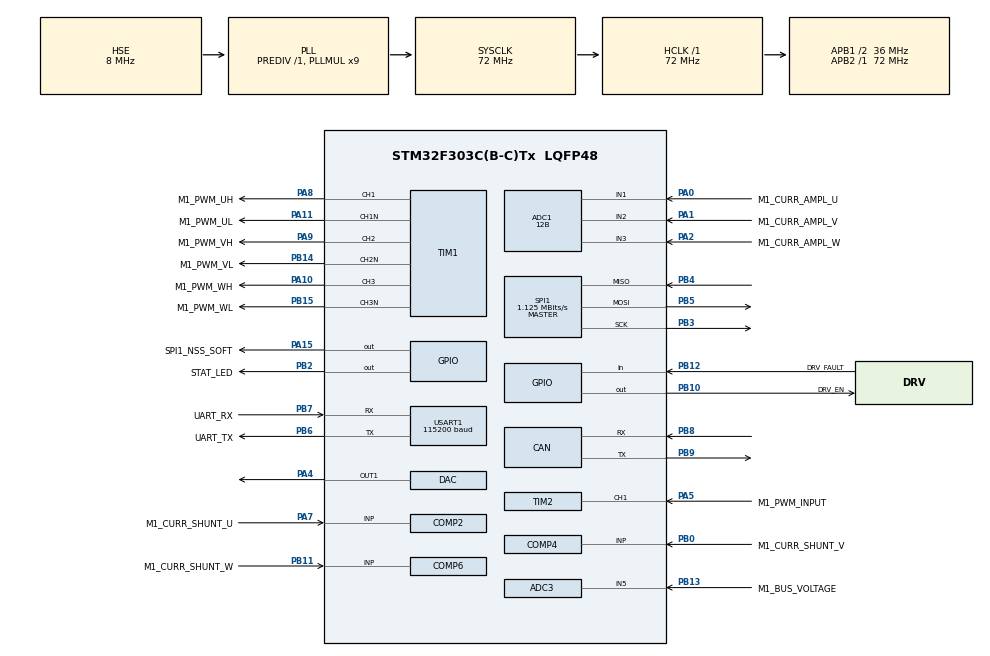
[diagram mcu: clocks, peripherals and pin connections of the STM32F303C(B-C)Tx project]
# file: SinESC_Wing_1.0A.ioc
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ADC1.Channel-1\#ChannelRegularConversion=ADC_CHANNEL_1
ADC1.ClockPrescaler=ADC_CLOCK_SYNC_PCLK_DIV1
ADC1.ContinuousConvMode=DISABLE
ADC1.DMAContinuousRequests=DISABLE
ADC1.DataAlign=ADC_DATAALIGN_LEFT
ADC1.DiscontinuousConvMode=DISABLE
ADC1.EOCSelection=ADC_EOC_SINGLE_CONV
ADC1.EnableAnalogWatchDog1=false
ADC1.EnableAnalogWatchDog2=false
ADC1.EnableAnalogWatchDog3=false
ADC1.EnableInjectedConversion=ENABLE
ADC1.EnableRegularConversion=ENABLE
ADC1.ExternalTrigConv=ADC_SOFTWARE_START
ADC1.ExternalTrigConvEdge=ADC_EXTERNALTRIGCONVEDGE_NONE
ADC1.ExternalTrigInjecConv=ADC_EXTERNALTRIGINJECCONV_T1_TRGO
ADC1.ExternalTrigInjecConvEdge=ADC_EXTERNALTRIGINJECCONV_EDGE_RISING
ADC1.InjNumberOfConversion=3
ADC1.InjectedChannel-1\#ChannelInjectedConversion=ADC_CHANNEL_1
ADC1.InjectedChannel-2\#ChannelInjectedConversion=ADC_CHANNEL_2
ADC1.InjectedChannel-3\#ChannelInjectedConversion=ADC_CHANNEL_3
ADC1.InjectedConvMode=None
ADC1.InjectedOffset-1\#ChannelInjectedConversion=0
ADC1.InjectedOffset-2\#ChannelInjectedConversion=0
ADC1.InjectedOffset-3\#ChannelInjectedConversion=0
ADC1.InjectedOffsetNumber-1\#ChannelInjectedConversion=ADC_OFFSET_NONE
ADC1.InjectedOffsetNumber-2\#ChannelInjectedConversion=ADC_OFFSET_NONE
ADC1.InjectedOffsetNumber-3\#ChannelInjectedConversion=ADC_OFFSET_NONE
ADC1.InjectedRank-1\#ChannelInjectedConversion=1
ADC1.InjectedRank-2\#ChannelInjectedConversion=2
ADC1.InjectedRank-3\#ChannelInjectedConversion=3
ADC1.InjectedSamplingTime-1\#ChannelInjectedConversion=ADC_SAMPLETIME_7CYCLES_5
ADC1.InjectedSamplingTime-2\#ChannelInjectedConversion=ADC_SAMPLETIME_7CYCLES_5
ADC1.InjectedSamplingTime-3\#ChannelInjectedConversion=ADC_SAMPLETIME_7CYCLES_5
ADC1.LowPowerAutoWait=DISABLE
ADC1.NbrOfConversion=1
ADC1.NbrOfConversionFlag=1
ADC1.Offset-1\#ChannelRegularConversion=0
ADC1.OffsetNumber-1\#ChannelRegularConversion=ADC_OFFSET_NONE
ADC1.Overrun=ADC_OVR_DATA_PRESERVED
ADC1.QueueInjectedContext=ENABLE
ADC1.Rank-1\#ChannelRegularConversion=1
ADC1.Resolution=ADC_RESOLUTION_12B
ADC1.SamplingTime-1\#ChannelRegularConversion=ADC_SAMPLETIME_19CYCLES_5
ADC1.ScanConvMode=ADC_SCAN_ENABLE
ADC1.master=1
ADC3.Channel-1\#ChannelRegularConversion=ADC_CHANNEL_5
ADC3.ClockPrescaler=ADC_CLOCK_SYNC_PCLK_DIV1
ADC3.ContinuousConvMode=DISABLE
ADC3.DMAContinuousRequests=DISABLE
ADC3.DataAlign=ADC_DATAALIGN_LEFT
ADC3.DiscontinuousConvMode=DISABLE
ADC3.EOCSelection=ADC_EOC_SINGLE_CONV
ADC3.EnableAnalogWatchDog1=false
ADC3.EnableAnalogWatchDog2=false
ADC3.EnableAnalogWatchDog3=false
ADC3.EnableRegularConversion=ENABLE
ADC3.ExternalTrigConv=ADC_SOFTWARE_START
ADC3.ExternalTrigConvEdge=ADC_EXTERNALTRIGCONVEDGE_NONE
ADC3.LowPowerAutoWait=DISABLE
ADC3.NbrOfConversion=1
ADC3.NbrOfConversionFlag=1
ADC3.Offset-1\#ChannelRegularConversion=0
ADC3.OffsetNumber-1\#ChannelRegularConversion=ADC_OFFSET_NONE
ADC3.Overrun=ADC_OVR_DATA_PRESERVED
ADC3.Rank-1\#ChannelRegularConversion=1
ADC3.Resolution=ADC_RESOLUTION_12B
ADC3.SamplingTime-1\#ChannelRegularConversion=ADC_SAMPLETIME_19CYCLES_5
ADC3.ScanConvMode=ADC_SCAN_DISABLE
ADC3.master=1
CAN.CalculateTimeQuantum=444.44444444444446
COMP2.InvertingInput=COMP_INVERTINGINPUT_1_2VREFINT
COMP2.Output=COMP_OUTPUT_TIM1BKIN2
COMP4.InvertingInput=COMP_INVERTINGINPUT_1_2VREFINT
COMP4.Output=COMP_OUTPUT_TIM1BKIN2
COMP6.InvertingInput=COMP_INVERTINGINPUT_1_2VREFINT
COMP6.Output=COMP_OUTPUT_TIM1BKIN2
ExtraMW=MotorControl
ExtraMW.MotorControl.Config=MotorControl
ExtraMW.MotorControl.Mode=MotorControl
ExtraMW.MotorControl.Root=MCSDK_v5.4.4/MotorControl
ExtraMW.MotorControl.Template=templates
Mcu.Family=STM32F3
Mcu.Name=STM32F303C(B-C)Tx
Mcu.Package=LQFP48
MotorControl.ADC_1_PERIPH=ADC1
MotorControl.ADC_2_PERIPH=ADC2
MotorControl.ADC_AHBPERIPH=RCC_AHBPeriph_ADC12
MotorControl.ADC_CLOCK_WB_DIV=1
MotorControl.ADC_CLOCK_WB_FREQ=72
MotorControl.ADC_PERIPH=ADC1
MotorControl.ADC_REFERENCE_VOLTAGE=3.30
MotorControl.ALIGNMENT_ANGLE_DEG=90
MotorControl.ALIGNMENT_DURATION=700
MotorControl.AMPLIFICATION_GAIN=29.77
MotorControl.ANGC={0,0,0,0,0,0,0,0}
MotorControl.BEMF_CONSISTENCY_GAIN=64
MotorControl.BEMF_CONSISTENCY_TOL=64
MotorControl.BKIN1_FILTER=0
MotorControl.BKIN2_FILTER=3
MotorControl.BKIN2_MODE=INT_MODE
MotorControl.BKIN_MODE=NONE
MotorControl.BOARD=CUSTOM
MotorControl.BRKIN2_GPIO_AF=GPIO_AF_2
MotorControl.BRKIN_GPIO_AF=GPIO_AF_12
MotorControl.BUS_VOLTAGE_READING=true
MotorControl.CCMRAM_ENABLED=false
MotorControl.CLOCK_FREQUENCY=CPU_CLK_72_MHZ
MotorControl.CLOCK_SOURCE=EXTERNAL
MotorControl.CONSTANT1_D=222297
MotorControl.CONSTANT1_Q=222297
MotorControl.CONSTANT2_QD=37693
MotorControl.CORD_BEMF_CONSISTENCY_GAIN=64
MotorControl.CORD_BEMF_CONSISTENCY_TOL=64
MotorControl.CORD_F1=16384
MotorControl.CORD_F2=8192
MotorControl.CORD_FIFO_DEPTH_01HZ=64
MotorControl.CORD_FIFO_DEPTH_DPP=64
MotorControl.CORD_GAIN1=-18535
MotorControl.CORD_GAIN2=22294
MotorControl.CORD_MAX_ACCEL_DPPP=30
MotorControl.CORD_MEAS_ERRORS_BEFORE_FAULTS=3
MotorControl.CORD_VARIANCE_THRESHOLD=4
MotorControl.CPU_CLK_72_MHZ=true
MotorControl.CTRBDID=10013
MotorControl.CUBE_MX_VER=5.6.1
MotorControl.CURRENT_READING_TOPOLOGY=THREE_SHUNT
MotorControl.CURR_SAMPLING_TIME=1
MotorControl.DAC_EMULATED=false
MotorControl.DAC_FUNCTIONALITY=false
MotorControl.DAC_TIMER_CH1_GPIO_PIN=LL_GPIO_PIN_4
MotorControl.DAC_TIMER_CH1_GPIO_PORT=GPIOA
MotorControl.DAC_TIMER_CH2_GPIO_PIN=LL_GPIO_PIN_0
MotorControl.DAC_TIMER_CH2_GPIO_PORT=GPIOA
MotorControl.DAC_TIMER_SELECTION=TIM3
MotorControl.DC_CURRENT_RS_MEAS=21.00
MotorControl.DEBUG_DAC_CH1=false
MotorControl.DEBUG_DAC_CH2=false
MotorControl.DEFAULT_CONTROL_MODE=STC_SPEED_MODE
MotorControl.DEFAULT_DAC_CHANNEL_1=MC_PROTOCOL_REG_DAC_USER1
MotorControl.DEFAULT_DAC_CHANNEL_2=MC_PROTOCOL_REG_I_B
MotorControl.DEFAULT_DAC_MOTOR=0
MotorControl.DEFAULT_FLUX_COMPONENT=0
MotorControl.DEFAULT_TARGET_SPEED_RPM=1000
MotorControl.DEFAULT_TORQUE_COMPONENT=0
MotorControl.DISSIPATIVE_BRAKE_POLARITY=DOUT_ACTIVE_HIGH
MotorControl.DRIVES_NUMBER_SELECTION=SINGLEDRIVE
MotorControl.EMERGENCY2_STOP_GPIO_PIN=LL_GPIO_PIN_11
MotorControl.EMERGENCY2_STOP_GPIO_PORT=GPIOA
MotorControl.EMERGENCY_STOP_GPIO_PIN=LL_GPIO_PIN_11
MotorControl.EMERGENCY_STOP_GPIO_PORT=GPIOA
MotorControl.ENABLE_SL_ALGO_FROM_PHASE=3
MotorControl.ENCODER_AVAILABLE=false
MotorControl.ENCODER_PPR=400
MotorControl.ENC_AVERAGING_FIFO_DEPTH=16
MotorControl.ENC_A_GPIO_PIN=LL_GPIO_PIN_0
MotorControl.ENC_A_GPIO_PORT=GPIOA
MotorControl.ENC_B_GPIO_PIN=LL_GPIO_PIN_1
MotorControl.ENC_B_GPIO_PORT=GPIOA
MotorControl.ENC_ICx_FILTER=50
MotorControl.ENC_INVERT_SPEED=false
MotorControl.ENC_MEAS_ERRORS_BEFORE_FAULTS=3
MotorControl.ENC_TIMER_REMAPPING=NO_REMAP_TIM2
MotorControl.ENC_TIMER_SELECTION=ENC_TIM2
MotorControl.ENC_USE_CH3=false
MotorControl.EXT_CLK_8_MHZ=true
MotorControl.EXT_CLOCK_FREQUENCY=EXT_CLK_8_MHZ
MotorControl.F1=16384
MotorControl.F2=8192
MotorControl.FEEDBACK_NET_FILTERING=false
MotorControl.FEED_FORWARD_CURRENT_REG_ENABLING=false
MotorControl.FINAL_I_ALIGNMENT=1152
MotorControl.FLUX_WEAKENING_ENABLING=false
MotorControl.FW_KIDIV=32768
MotorControl.FW_KI_GAIN=5000
MotorControl.FW_KPDIV=32768
MotorControl.FW_KP_GAIN=3000
MotorControl.FW_VOLTAGE_REF=985
MotorControl.GAIN1=-18535
MotorControl.GAIN2=22294
MotorControl.H1_GPIO_PIN=LL_GPIO_PIN_0
MotorControl.H1_GPIO_PORT=GPIOA
MotorControl.H2_GPIO_PIN=LL_GPIO_PIN_1
MotorControl.H2_GPIO_PORT=GPIOA
MotorControl.H3_GPIO_PIN=LL_GPIO_PIN_2
MotorControl.H3_GPIO_PORT=GPIOA
MotorControl.HALL_AVERAGING_FIFO_DEPTH=6
MotorControl.HALL_ICx_FILTER=94
MotorControl.HALL_MEAS_ERRORS_BEFORE_FAULTS=3
MotorControl.HALL_MTPA=false
MotorControl.HALL_PHASE_SHIFT=300
MotorControl.HALL_SENSORS_AVAILABLE=false
MotorControl.HALL_SENSORS_PLACEMENT=DEGREES_120
MotorControl.HALL_TIMER_REMAPPING=NO_REMAP_TIM2
MotorControl.HALL_TIMER_SELECTION=HALL_TIM2
MotorControl.HFI_AMPLITUDE=25
MotorControl.HFI_DC_0_COEFF=0.00146
MotorControl.HFI_DC_1_COEFF=0.002921
MotorControl.HFI_DC_2_COEFF=0.00146
MotorControl.HFI_DC_3_COEFF=1.889033
MotorControl.HFI_DC_4_COEFF=-0.894874
MotorControl.HFI_DEBUG_MODE=false
MotorControl.HFI_FREQUENCY=400
MotorControl.HFI_HIFRAMPLSCAN=25
MotorControl.HFI_HP_ID_0_COEFF=0.959381
MotorControl.HFI_HP_ID_1_COEFF=-1.918761
MotorControl.HFI_HP_ID_2_COEFF=0.959381
MotorControl.HFI_HP_ID_3_COEFF=1.917111
MotorControl.HFI_HP_ID_4_COEFF=-0.920412
MotorControl.HFI_IDH_DELAY=32400
MotorControl.HFI_LOCKFREQ=22
MotorControl.HFI_LP_ID_0_COEFF=0.002751
MotorControl.HFI_LP_ID_1_COEFF=0.005502
MotorControl.HFI_LP_ID_2_COEFF=0.002751
MotorControl.HFI_LP_ID_3_COEFF=1.846252
MotorControl.HFI_LP_ID_4_COEFF=-0.857255
MotorControl.HFI_MAXANGLEDIFF=3640
MotorControl.HFI_MINIMUM_SPEED_RPM=402
MotorControl.HFI_NOTCH_IQD_0_COEFF=0.979509
MotorControl.HFI_NOTCH_IQD_1_COEFF=-1.952148
MotorControl.HFI_NOTCH_IQD_2_COEFF=0.979509
MotorControl.HFI_NOTCH_IQD_3_COEFF=1.952148
MotorControl.HFI_NOTCH_IQD_4_COEFF=-0.959018
MotorControl.HFI_NSDETPOINTSSKIP=10
MotorControl.HFI_NSMAXDETPOINTS=20
MotorControl.HFI_NS_MIN_SAT_DIFF=0
MotorControl.HFI_PID_KIDIV=32768
MotorControl.HFI_PID_KI_DEFAULT=400
MotorControl.HFI_PID_KPDIV=16384
MotorControl.HFI_PID_KP_DEFAULT=800
MotorControl.HFI_PLL_KI_DEFAULT=0.00400
MotorControl.HFI_PLL_KP_DEFAULT=0.00060
MotorControl.HFI_RESTARTTIMESEC=0.1
MotorControl.HFI_RESTART_RPM_TH=(((HFI_STO_RPM_TH)+(STO_HFI_RPM_TH))/2)
MotorControl.HFI_REVERT_DIRECTION=true
MotorControl.HFI_SCANROTATIONSNO=3
MotorControl.HFI_SPD_BUFFER_DEPTH_01HZ=64
MotorControl.HFI_STEPANGLE=3640
MotorControl.HFI_STO_RPM_TH=OBS_MINIMUM_SPEED_RPM
MotorControl.HFI_WAITAFTERNS2=4
MotorControl.HFI_WAITBEFORESN=6
MotorControl.HFI_WAITSYNCH=20
MotorControl.HFI_WAITTRACK=20
MotorControl.HIGH_SIDE_BRAKE_STATE=false
MotorControl.HIGH_SIDE_IDLE_STATE=false
MotorControl.HW_COMPLEMENTED_LOW_SIDE=false
MotorControl.HW_DEAD_TIME_NS=500
MotorControl.HW_OV_CURRENT_PROT_BYPASS=false
MotorControl.ID_DEMAG=-12415
MotorControl.INRUSH_CURRLIMIT_AT_POWER_ON=false
MotorControl.INRUSH_CURRLIMIT_CHANGE_AFTER_MS=1000
MotorControl.INRUSH_CURRLIMIT_ENABLING=false
MotorControl.INRUSH_CURRLIMIT_GPIO_PIN=LL_GPIO_PIN_4
MotorControl.INRUSH_CURRLIMIT_GPIO_PORT=GPIOD
MotorControl.INRUSH_CURR_LIMITER_POLARITY=DOUT_ACTIVE_HIGH
MotorControl.INTERNAL_OVERCURRENTPROTECTION=true
MotorControl.INTERNAL_OVERVOLTAGEPROTECTION=false
MotorControl.IQMAX=12415
MotorControl.LCD_JOYSTICK_FUNCTIONALITY=false
MotorControl.LCD_MODE=LCD_FULL
MotorControl.LDLQ_RATIO=1.000
MotorControl.LOW_SIDE_BRAKE_STATE=false
MotorControl.LOW_SIDE_IDLE_STATE=false
MotorControl.LOW_SIDE_SIGNALS_ENABLING=LS_PWM_TIMER
MotorControl.LS=0.000040
MotorControl.MAX_APPLICATION_SPEED=6000
MotorControl.MAX_MODULATION_81_PER_CENT=true
MotorControl.MAX_MODULATION_INDEX=MAX_MODULATION_81_PER_CENT
MotorControl.MCU=STM32F303CB
MotorControl.MCU_TYPE=STM32F303xB
MotorControl.MC_WORKBENCH_VERSION=5.4.4.20160
MotorControl.MEAS_ERRORS_BEFORE_FAULTS=3
MotorControl.MIN_APPLICATION_SPEED=0
MotorControl.MOTOR_MAX_SPEED_RPM=6000
MotorControl.MOTOR_TYPE=PMSM
MotorControl.MOTOR_VOLTAGE_CONSTANT=2.7
MotorControl.MTPA_ENABLING=false
MotorControl.NB_CONSECUTIVE_TESTS=50
MotorControl.NOMINAL_BUS_VOLTAGE_V=16
MotorControl.NOMINAL_CURRENT=12415
MotorControl.OBS_MEAS_ERRORS_BEFORE_FAULTS=3
MotorControl.OBS_MINIMUM_SPEED_RPM=500
MotorControl.OCPA_INVERTINGINPUT=COMPX_InvertingInput_DAC1
MotorControl.OCPA_INVERTINGINPUT_GPIO_PIN=LL_GPIO_PIN_4
MotorControl.OCPA_INVERTINGINPUT_GPIO_PORT=GPIOA
MotorControl.OCPA_INVERTINGINPUT_MODE=INT_MODE
MotorControl.OCPA_NONINVERTINGINPUT=COMP2_NonInvertingInput_PA7
MotorControl.OCPA_NONINVERTINGINPUT_GPIO_PIN=LL_GPIO_PIN_7
MotorControl.OCPA_NONINVERTINGINPUT_GPIO_PORT=GPIOA
MotorControl.OCPA_OUTPUT=COMP_Output_TIM1BKIN2
MotorControl.OCPA_OUTPUTPOL=COMP_OutputPol_NonInverted
MotorControl.OCPA_OUTPUT_GPIO_AF=GPIO_AF_8
MotorControl.OCPA_OUTPUT_GPIO_PIN=LL_GPIO_PIN_2
MotorControl.OCPA_OUTPUT_GPIO_PORT=GPIOA
MotorControl.OCPA_OUTPUT_MODE=INT_MODE
MotorControl.OCPA_SELECTION=COMP2
MotorControl.OCPB_INVERTINGINPUT=COMPX_InvertingInput_DAC1
MotorControl.OCPB_INVERTINGINPUT_GPIO_PIN=LL_GPIO_PIN_4
MotorControl.OCPB_INVERTINGINPUT_GPIO_PORT=GPIOA
MotorControl.OCPB_INVERTINGINPUT_MODE=INT_MODE
MotorControl.OCPB_NONINVERTINGINPUT=COMP4_NonInvertingInput_PB0
MotorControl.OCPB_NONINVERTINGINPUT_GPIO_PIN=LL_GPIO_PIN_0
MotorControl.OCPB_NONINVERTINGINPUT_GPIO_PORT=GPIOB
MotorControl.OCPB_OUTPUT=COMP_Output_TIM1BKIN2
MotorControl.OCPB_OUTPUTPOL=COMP_OutputPol_NonInverted
MotorControl.OCPB_OUTPUT_GPIO_AF=GPIO_AF_8
MotorControl.OCPB_OUTPUT_GPIO_PIN=LL_GPIO_PIN_1
MotorControl.OCPB_OUTPUT_GPIO_PORT=GPIOB
MotorControl.OCPB_OUTPUT_MODE=INT_MODE
MotorControl.OCPB_SELECTION=COMP4
MotorControl.OCPC_INVERTINGINPUT=COMPX_InvertingInput_DAC1
MotorControl.OCPC_INVERTINGINPUT_GPIO_PIN=LL_GPIO_PIN_4
MotorControl.OCPC_INVERTINGINPUT_GPIO_PORT=GPIOA
MotorControl.OCPC_INVERTINGINPUT_MODE=INT_MODE
MotorControl.OCPC_NONINVERTINGINPUT=COMP6_NonInvertingInput_PB11
MotorControl.OCPC_NONINVERTINGINPUT_GPIO_PIN=LL_GPIO_PIN_11
MotorControl.OCPC_NONINVERTINGINPUT_GPIO_PORT=GPIOB
MotorControl.OCPC_OUTPUT=COMP_Output_TIM1BKIN2
MotorControl.OCPC_OUTPUTPOL=COMP_OutputPol_NonInverted
MotorControl.OCPC_OUTPUT_GPIO_AF=GPIO_AF_8
MotorControl.OCPC_OUTPUT_GPIO_PIN=LL_GPIO_PIN_10
MotorControl.OCPC_OUTPUT_GPIO_PORT=GPIOA
MotorControl.OCPC_OUTPUT_MODE=INT_MODE
MotorControl.OCPC_SELECTION=COMP6
MotorControl.OCPREF=6752
MotorControl.OCP_COMP_THRESHOLD=0.50
MotorControl.OCP_FILTER=COMP_Mode_HighSpeed
MotorControl.OCP_INVERTINGINPUT=COMPX_InvertingInput_DAC1
MotorControl.OCP_INVERTINGINPUT_GPIO_PIN=LL_GPIO_PIN_4
MotorControl.OCP_INVERTINGINPUT_GPIO_PORT=GPIOA
MotorControl.OCP_INVERTINGINPUT_MODE=INT_MODE
MotorControl.OCP_NONINVERTINGINPUT=COMP2_NonInvertingInput_PA7
MotorControl.OCP_NONINVERTINGINPUT_GPIO_PIN=LL_GPIO_PIN_7
MotorControl.OCP_NONINVERTINGINPUT_GPIO_PORT=GPIOA
MotorControl.OCP_OUTPUT=COMP_Output_TIM1BKIN2
MotorControl.OCP_OUTPUTPOL=COMP_OutputPol_NonInverted
MotorControl.OCP_OUTPUT_GPIO_AF=GPIO_AF_8
MotorControl.OCP_OUTPUT_GPIO_PIN=LL_GPIO_PIN_2
MotorControl.OCP_OUTPUT_GPIO_PORT=GPIOA
MotorControl.OCP_OUTPUT_MODE=INT_MODE
MotorControl.OCP_SELECTION=COMP2
MotorControl.OFST={0,0,0,0,0,0,0,0}
MotorControl.ON_OVER_VOLTAGE=TURN_OFF_PWM
MotorControl.OPAMP1_INVERTINGINPUT=OPAMP1_InvertingInput_PA3
MotorControl.OPAMP1_INVERTINGINPUT_GPIO_PIN=LL_GPIO_PIN_3
MotorControl.OPAMP1_INVERTINGINPUT_GPIO_PORT=GPIOA
MotorControl.OPAMP1_INVERTINGINPUT_MODE=EXT_MODE
MotorControl.OPAMP1_NONINVERTINGINPUT_PHA=OPAMP1_NonInvertingInput_PA1
MotorControl.OPAMP1_NONINVERTINGINPUT_PHA_GPIO_PIN=LL_GPIO_PIN_1
MotorControl.OPAMP1_NONINVERTINGINPUT_PHA_GPIO_PORT=GPIOA
MotorControl.OPAMP1_NONINVERTINGINPUT_PHB=OPAMP1_NonInvertingInput_PA7
MotorControl.OPAMP1_NONINVERTINGINPUT_PHB_GPIO_PIN=LL_GPIO_PIN_7
MotorControl.OPAMP1_NONINVERTINGINPUT_PHB_GPIO_PORT=GPIOA
MotorControl.OPAMP1_OUT_GPIO_PIN=LL_GPIO_PIN_2
MotorControl.OPAMP1_OUT_GPIO_PORT=GPIOA
MotorControl.OPAMP1_SELECTION=OPAMP1
MotorControl.OPAMP2_INVERTINGINPUT=OPAMP2_InvertingInput_PA5
MotorControl.OPAMP2_INVERTINGINPUT_GPIO_PIN=LL_GPIO_PIN_5
MotorControl.OPAMP2_INVERTINGINPUT_GPIO_PORT=GPIOA
MotorControl.OPAMP2_INVERTINGINPUT_MODE=EXT_MODE
MotorControl.OPAMP2_NONINVERTINGINPUT_PHA=OPAMP2_NonInvertingInput_PB0
MotorControl.OPAMP2_NONINVERTINGINPUT_PHA_GPIO_PIN=LL_GPIO_PIN_0
MotorControl.OPAMP2_NONINVERTINGINPUT_PHA_GPIO_PORT=GPIOB
MotorControl.OPAMP2_NONINVERTINGINPUT_PHB=OPAMP2_NonInvertingInput_PA7
MotorControl.OPAMP2_NONINVERTINGINPUT_PHB_GPIO_PIN=LL_GPIO_PIN_7
MotorControl.OPAMP2_NONINVERTINGINPUT_PHB_GPIO_PORT=GPIOA
MotorControl.OPAMP2_NONINVERTINGINPUT_PHC=OPAMP2_NonInvertingInput_PB0
MotorControl.OPAMP2_NONINVERTINGINPUT_PHC_GPIO_PIN=LL_GPIO_PIN_0
MotorControl.OPAMP2_NONINVERTINGINPUT_PHC_GPIO_PORT=GPIOB
MotorControl.OPAMP2_OUT_GPIO_PIN=LL_GPIO_PIN_6
MotorControl.OPAMP2_OUT_GPIO_PORT=GPIOA
MotorControl.OPAMP2_SELECTION=OPAMP2
MotorControl.OPAMP3_INVERTINGINPUT=OPAMP1_InvertingInput_PA0
MotorControl.OPAMP3_INVERTINGINPUT_GPIO_PIN=LL_GPIO_PIN_0
MotorControl.OPAMP3_INVERTINGINPUT_GPIO_PORT=GPIOA
MotorControl.OPAMP3_INVERTINGINPUT_MODE=EXT_MODE
MotorControl.OPAMP3_SELECTION=OPAMP1
MotorControl.OPAMP_INVERTINGINPUT=OPAMP1_InvertingInput_PA3
MotorControl.OPAMP_INVERTINGINPUT_GPIO_PIN=LL_GPIO_PIN_3
MotorControl.OPAMP_INVERTINGINPUT_GPIO_PORT=GPIOA
MotorControl.OPAMP_INVERTINGINPUT_MODE=EXT_MODE
MotorControl.OPAMP_NONINVERTINGINPUT=OPAMP1_NonInvertingInput_PA7
MotorControl.OPAMP_NONINVERTINGINPUT_GPIO_PIN=LL_GPIO_PIN_7
MotorControl.OPAMP_NONINVERTINGINPUT_GPIO_PORT=GPIOA
MotorControl.OPAMP_OUT_GPIO_PIN=LL_GPIO_PIN_2
MotorControl.OPAMP_OUT_GPIO_PORT=GPIOA
MotorControl.OPAMP_PGACONNECT=OPAMP1_PGAConnect_PA3
MotorControl.OPAMP_PGAGAIN=OPAMP_OPAMP_PGAGain_2
MotorControl.OPAMP_SELECTION=OPAMP1
MotorControl.OPAMP_TYPE_GAIN=EXTERNAL
MotorControl.OPEN_LOOP_FOC=false
MotorControl.OPEN_LOOP_K=44
MotorControl.OPEN_LOOP_OFF=4400
MotorControl.OPEN_LOOP_SPEED_RAMP_DURATION_MS=1000
MotorControl.OPEN_LOOP_SPEED_RPM=100
MotorControl.OPEN_LOOP_VF=false
MotorControl.OPEN_LOOP_VOLTAGE_d=6000
MotorControl.OVERCURR_FEEDBACK_POLARITY=EMSTOP2_ACTIVE_LOW
MotorControl.OVERCURR_PROTECTION_HW_DISABLING=DOUT_ACTIVE_HIGH
MotorControl.OVPREF=23830
MotorControl.OVP_FILTER=COMP_Mode_HighSpeed
MotorControl.OVP_INVERTINGINPUT=COMPX_InvertingInput_VREF
MotorControl.OVP_INVERTINGINPUT_GPIO_PIN=LL_GPIO_PIN_4
MotorControl.OVP_INVERTINGINPUT_GPIO_PORT=GPIOA
MotorControl.OVP_INVERTINGINPUT_MODE=INT_MODE
MotorControl.OVP_NONINVERTINGINPUT=COMP2_NonInvertingInput_PA7
MotorControl.OVP_NONINVERTINGINPUT_GPIO_PIN=LL_GPIO_PIN_7
MotorControl.OVP_NONINVERTINGINPUT_GPIO_PORT=GPIOA
MotorControl.OVP_OUTPUT=COMP_Output_TIM1BKIN
MotorControl.OVP_OUTPUTPOL=COMP_OutputPol_NonInverted
MotorControl.OVP_OUTPUT_GPIO_AF=GPIO_AF_8
MotorControl.OVP_OUTPUT_GPIO_PIN=LL_GPIO_PIN_2
MotorControl.OVP_OUTPUT_GPIO_PORT=GPIOA
MotorControl.OVP_OUTPUT_MODE=INT_MODE
MotorControl.OVP_SELECTION=COMP2
MotorControl.OV_CURR_BYPASS_GPIO_PIN=LL_GPIO_PIN_5
MotorControl.OV_CURR_BYPASS_GPIO_PORT=GPIOD
MotorControl.OV_TEMPERATURE_HYSTERESIS_C=10
MotorControl.OV_TEMPERATURE_PROT_ENABLING=false
MotorControl.OV_TEMPERATURE_THRESHOLD_C=110
MotorControl.OV_VOLTAGE_PROT_ENABLING=true
MotorControl.OV_VOLTAGE_THRESHOLD_V=30
MotorControl.PHASE1_DURATION=0
MotorControl.PHASE1_FINAL_CURRENT=0
MotorControl.PHASE1_FINAL_SPEED_RPM=0
MotorControl.PHASE2_DURATION=1500
MotorControl.PHASE2_FINAL_CURRENT=443
MotorControl.PHASE2_FINAL_SPEED_RPM=0
MotorControl.PHASE3_DURATION=1000
MotorControl.PHASE3_FINAL_CURRENT=443
MotorControl.PHASE3_FINAL_SPEED_RPM=1000
MotorControl.PHASE4_DURATION=0
MotorControl.PHASE4_FINAL_CURRENT=443
MotorControl.PHASE4_FINAL_SPEED_RPM=1000
MotorControl.PHASE5_DURATION=0
MotorControl.PHASE5_FINAL_CURRENT=443
MotorControl.PHASE5_FINAL_SPEED_RPM=1000
MotorControl.PHASE_CURRENTS_ADC=ADC1_2
MotorControl.PHASE_CURRENTS_CHANNEL=ADC_CHANNEL_9
MotorControl.PHASE_CURRENTS_GPIO_PIN=LL_GPIO_PIN_3
MotorControl.PHASE_CURRENTS_GPIO_PORT=GPIOC
MotorControl.PHASE_UH_GPIO_AF=GPIO_AF_6
MotorControl.PHASE_UH_GPIO_PIN=LL_GPIO_PIN_8
MotorControl.PHASE_UH_GPIO_PORT=GPIOA
MotorControl.PHASE_UH_POLARITY=H_ACTIVE_HIGH
MotorControl.PHASE_UL_GPIO_AF=GPIO_AF_6
MotorControl.PHASE_UL_GPIO_PIN=LL_GPIO_PIN_11
MotorControl.PHASE_UL_GPIO_PORT=GPIOA
MotorControl.PHASE_UL_POLARITY=L_ACTIVE_HIGH
MotorControl.PHASE_U_CURR_ADC=ADC1
MotorControl.PHASE_U_CURR_CHANNEL=ADC_CHANNEL_1
MotorControl.PHASE_U_GPIO_PIN=LL_GPIO_PIN_0
MotorControl.PHASE_U_GPIO_PORT=GPIOA
MotorControl.PHASE_VH_GPIO_AF=GPIO_AF_6
MotorControl.PHASE_VH_GPIO_PIN=LL_GPIO_PIN_9
MotorControl.PHASE_VH_GPIO_PORT=GPIOA
MotorControl.PHASE_VH_POLARITY=H_ACTIVE_HIGH
MotorControl.PHASE_VL_GPIO_AF=GPIO_AF_6
MotorControl.PHASE_VL_GPIO_PIN=LL_GPIO_PIN_14
MotorControl.PHASE_VL_GPIO_PORT=GPIOB
MotorControl.PHASE_VL_POLARITY=L_ACTIVE_HIGH
MotorControl.PHASE_V_CURR_ADC=ADC1
MotorControl.PHASE_V_CURR_CHANNEL=ADC_CHANNEL_2
MotorControl.PHASE_V_GPIO_PIN=LL_GPIO_PIN_1
MotorControl.PHASE_V_GPIO_PORT=GPIOA
MotorControl.PHASE_WH_GPIO_AF=GPIO_AF_6
MotorControl.PHASE_WH_GPIO_PIN=LL_GPIO_PIN_10
MotorControl.PHASE_WH_GPIO_PORT=GPIOA
MotorControl.PHASE_WH_POLARITY=H_ACTIVE_HIGH
MotorControl.PHASE_WL_GPIO_AF=GPIO_AF_4
MotorControl.PHASE_WL_GPIO_PIN=LL_GPIO_PIN_15
MotorControl.PHASE_WL_GPIO_PORT=GPIOB
MotorControl.PHASE_WL_POLARITY=L_ACTIVE_HIGH
MotorControl.PHASE_W_CURR_ADC=ADC1
MotorControl.PHASE_W_CURR_CHANNEL=ADC_CHANNEL_3
MotorControl.PHASE_W_GPIO_PIN=LL_GPIO_PIN_2
MotorControl.PHASE_W_GPIO_PORT=GPIOA
MotorControl.PID_FLUX_KD_DEFAULT=100
MotorControl.PID_FLUX_KI_DEFAULT=3349
MotorControl.PID_FLUX_KP_DEFAULT=3405
MotorControl.PID_SPEED_KD_DEFAULT=0
MotorControl.PID_SPEED_KI_DEFAULT=25
MotorControl.PID_SPEED_KP_DEFAULT=3105
MotorControl.PID_TORQUE_KD_DEFAULT=100
MotorControl.PID_TORQUE_KI_DEFAULT=3349
MotorControl.PID_TORQUE_KP_DEFAULT=3405
MotorControl.PLL_KI_GAIN=17
MotorControl.PLL_KP_GAIN=745
MotorControl.POLE_PAIR_NUM=7
MotorControl.POSITION_CTRL_ENABLING=false
MotorControl.PWBDID=10013
MotorControl.PWM_FREQUENCY=60000
MotorControl.PWM_TIMER_REMAPPING=PWM_PARTIAL_REMAP
MotorControl.PWM_TIMER_SELECTION=PWM_TIM1
MotorControl.REGCONVADC=ADC3
MotorControl.REGULATION_EXECUTION_RATE=2
MotorControl.RS=0.59
MotorControl.RSHUNT=0.00100
MotorControl.RTOS=NONE
MotorControl.R_BRAKE_GPIO_PIN=LL_GPIO_PIN_5
MotorControl.R_BRAKE_GPIO_PORT=GPIOD
MotorControl.R_BRAKE_SWITCH_OFF_THRES_V=24
MotorControl.SEGDIV=0
MotorControl.SERIAL_COMMUNICATION=true
MotorControl.SERIAL_COM_CHANNEL1=MC_PROTOCOL_REG_I_A
MotorControl.SERIAL_COM_CHANNEL2=MC_PROTOCOL_REG_I_A
MotorControl.SERIAL_COM_MODE=COM_BIDIRECTIONAL
MotorControl.SERIAL_COM_MOTOR=0
MotorControl.SHARED_SIGNAL_ENABLE=false
MotorControl.SINGLEDRIVE=true
MotorControl.SPD_DIFFERENTIAL_TERM_ENABLING=false
MotorControl.SPEED_BAND_LOWER_LIMIT=15
MotorControl.SPEED_BAND_UPPER_LIMIT=17
MotorControl.SPEED_FEEDBACK_CHECK=true
MotorControl.SPEED_LOOP_FREQUENCY_HZ=2000
MotorControl.SPEED_SENSOR_SELECTION=STATE_OBSERVER_PLL
MotorControl.SP_KDDIV=16
MotorControl.SP_KIDIV=16384
MotorControl.SP_KPDIV=1024
MotorControl.STARTING_ANGLE_DEG=90
MotorControl.START_STOP_BTN=false
MotorControl.START_STOP_GPIO_PIN=LL_GPIO_PIN_13
MotorControl.START_STOP_GPIO_PORT=GPIOC
MotorControl.START_STOP_POLARITY=DIN_ACTIVE_LOW
MotorControl.START_STOP_POLARITY_EDGE=GPIO_NOPULL
MotorControl.STATE_OBSERVER_PLL=true
MotorControl.STM32F303xB=true
MotorControl.STO_FIFO_DEPTH_01HZ=64
MotorControl.STO_FIFO_DEPTH_DPP=64
MotorControl.STO_HFI_RPM_TH=460
MotorControl.SW_DEADTIME_NS=700
MotorControl.SW_OV_CURRENT_PROT_ENABLING=true
MotorControl.T0_C=25
MotorControl.TEMPERATURE_READING=false
MotorControl.TEMP_ADC_SAMPLING_TIME=19
MotorControl.TEMP_FDBK_ADC=ADC1
MotorControl.TEMP_FDBK_CHANNEL=ADC_CHANNEL_4
MotorControl.TEMP_FDBK_GPIO_PIN=LL_GPIO_PIN_3
MotorControl.TEMP_FDBK_GPIO_PORT=GPIOA
MotorControl.TFDIFFERENTIAL_TERM_ENABLING=false
MotorControl.TF_KDDIV=8192
MotorControl.TF_KIDIV=4096
MotorControl.TF_KPDIV=2048
MotorControl.THREE_SHUNT=true
MotorControl.TNOISE_NS=1000
MotorControl.TRANSITION_DURATION=50
MotorControl.TRISE_NS=1000
MotorControl.T_MAX=110
MotorControl.UD_VOLTAGE_THRESHOLD_V=12
MotorControl.USART_REMAPPING=NO_REMAP_USART1
MotorControl.USART_RX_GPIO_PIN=LL_GPIO_PIN_7
MotorControl.USART_RX_GPIO_PORT=GPIOB
MotorControl.USART_SELECTION=USE_USART1
MotorControl.USART_SPEED=115200
MotorControl.USART_TX_GPIO_PIN=LL_GPIO_PIN_6
MotorControl.USART_TX_GPIO_PORT=GPIOB
MotorControl.USE_3OPAMPS=false
MotorControl.USE_INTERNAL_OPAMP=false
MotorControl.UV_VOLTAGE_PROT_ENABLING=true
MotorControl.V0_V=1.055
MotorControl.VARIANCE_THRESHOLD=0.1
MotorControl.VBUS_ADC=ADC3
MotorControl.VBUS_ADC_SAMPLING_TIME=19
MotorControl.VBUS_CHANNEL=ADC_CHANNEL_5
MotorControl.VBUS_GPIO_PIN=LL_GPIO_PIN_13
MotorControl.VBUS_GPIO_PORT=GPIOB
MotorControl.VBUS_PARTITIONING_FACTOR=0.1071
MotorControl.WB_to_Mx_template_version=20-04-17
MotorControl.WB_to_Mx_version=1.1.0
MotorControl.dV_dT=0.023
NVIC.ADC1_2_IRQn=true\:2\:0\:true\:true\:false\:3\:true\:true
NVIC.PriorityGroup=NVIC_PRIORITYGROUP_3
NVIC.TIM1_BRK_TIM15_IRQn=true\:4\:1\:true\:true\:false\:1\:true\:true
NVIC.TIM1_UP_TIM16_IRQn=true\:0\:0\:false\:true\:false\:2\:true\:true
NVIC.TIM2_IRQn=true\:3\:0\:true\:true\:false\:5\:true\:true
NVIC.USART1_IRQn=true\:3\:1\:true\:true\:false\:4\:true\:true
PA0.GPIO_Label=M1_CURR_AMPL_U
PA0.Mode=IN1-Single-Ended
PA0.Signal=ADC1_IN1
PA1.GPIO_Label=M1_CURR_AMPL_V
PA1.Mode=IN2-Single-Ended
PA1.Signal=ADC1_IN2
PA10.GPIO_Label=M1_PWM_WH
PA10.GPIO_PuPd=GPIO_PULLDOWN
PA10.GPIO_Speed=GPIO_SPEED_FREQ_HIGH
PA10.Signal=S_TIM1_CH3
PA11.GPIO_Label=M1_PWM_UL
PA11.GPIO_PuPd=GPIO_PULLUP
PA11.GPIO_Speed=GPIO_SPEED_FREQ_HIGH
PA11.Mode=PWM Generation1 CH1 CH1N
PA11.Signal=TIM1_CH1N
PA13.Signal=SYS_JTMS-SWDIO
PA14.Signal=SYS_JTCK-SWCLK
PA15.GPIO_Label=SPI1_NSS_SOFT
PA15.GPIO_PuPd=GPIO_PULLUP
PA15.GPIO_Speed=GPIO_SPEED_FREQ_HIGH
PA15.Signal=GPIO_Output
PA2.GPIO_Label=M1_CURR_AMPL_W
PA2.Mode=IN3-Single-Ended
PA2.Signal=ADC1_IN3
PA4.Signal=COMP_DAC1_group
PA5.GPIO_Label=M1_PWM_INPUT
PA5.GPIO_PuPd=GPIO_PULLDOWN
PA5.GPIO_Speed=GPIO_SPEED_FREQ_HIGH
PA5.Signal=S_TIM2_CH1_ETR
PA7.GPIO_Label=M1_CURR_SHUNT_U
PA7.Mode=INP
PA7.Signal=COMP2_INP
PA8.GPIO_Label=M1_PWM_UH
PA8.GPIO_PuPd=GPIO_PULLDOWN
PA8.GPIO_Speed=GPIO_SPEED_FREQ_HIGH
PA8.Signal=S_TIM1_CH1
PA9.GPIO_Label=M1_PWM_VH
PA9.GPIO_PuPd=GPIO_PULLDOWN
PA9.GPIO_Speed=GPIO_SPEED_FREQ_HIGH
PA9.Signal=S_TIM1_CH2
PB0.GPIO_Label=M1_CURR_SHUNT_V
PB0.Mode=INP
PB0.Signal=COMP4_INP
PB10.GPIO_Label=DRV_EN
PB10.GPIO_PuPd=GPIO_PULLUP
PB10.PinState=GPIO_PIN_SET
PB10.Signal=GPIO_Output
PB11.GPIO_Label=M1_CURR_SHUNT_W
PB11.Mode=INP
PB11.Signal=COMP6_INP
PB12.GPIO_Label=DRV_FAULT
PB12.Signal=GPIO_Input
PB13.GPIO_Label=M1_BUS_VOLTAGE
PB13.Mode=IN5-Single-Ended
PB13.Signal=ADC3_IN5
PB14.GPIO_Label=M1_PWM_VL
PB14.GPIO_PuPd=GPIO_PULLUP
PB14.GPIO_Speed=GPIO_SPEED_FREQ_HIGH
PB14.Mode=PWM Generation2 CH2 CH2N
PB14.Signal=TIM1_CH2N
PB15.GPIO_Label=M1_PWM_WL
PB15.GPIO_PuPd=GPIO_PULLUP
PB15.GPIO_Speed=GPIO_SPEED_FREQ_HIGH
PB15.Mode=PWM Generation3 CH3 CH3N
PB15.Signal=TIM1_CH3N
PB2.GPIO_Label=STAT_LED
PB2.GPIO_PuPd=GPIO_PULLDOWN
PB2.Signal=GPIO_Output
PB3.GPIO_PuPd=GPIO_PULLUP
PB3.Mode=Full_Duplex_Master
PB3.Signal=SPI1_SCK
PB4.GPIO_PuPd=GPIO_PULLUP
PB4.Mode=Full_Duplex_Master
PB4.Signal=SPI1_MISO
PB5.GPIO_PuPd=GPIO_PULLUP
PB5.Mode=Full_Duplex_Master
PB5.Signal=SPI1_MOSI
PB6.GPIO_Label=UART_TX
PB6.GPIO_Mode=GPIO_MODE_AF_PP
PB6.GPIO_PuPd=GPIO_NOPULL
PB6.GPIO_Speed=GPIO_SPEED_FREQ_LOW
PB6.Mode=Asynchronous
PB6.Signal=USART1_TX
PB7.GPIO_Label=UART_RX
PB7.GPIO_Mode=GPIO_MODE_AF_PP
PB7.GPIO_PuPd=GPIO_NOPULL
PB7.GPIO_Speed=GPIO_SPEED_FREQ_LOW
PB7.Mode=Asynchronous
PB7.Signal=USART1_RX
PB8.Mode=Master
PB8.Signal=CAN_RX
PB9.Mode=Master
PB9.Signal=CAN_TX
PF0-OSC_IN.Mode=HSE-External-Oscillator
PF0-OSC_IN.Signal=RCC_OSC_IN
PF1-OSC_OUT.Mode=HSE-External-Oscillator
PF1-OSC_OUT.Signal=RCC_OSC_OUT
ProjectManager.HeapSize=0x200
ProjectManager.StackSize=0x400
ProjectManager.TargetToolchain=STM32CubeIDE
RCC.AHBFreq_Value=72000000
RCC.APB1CLKDivider=RCC_HCLK_DIV2
RCC.APB1Freq_Value=36000000
RCC.APB1TimFreq_Value=72000000
RCC.APB2Freq_Value=72000000
RCC.APB2TimFreq_Value=72000000
RCC.CortexFreq_Value=72000000
RCC.HCLKFreq_Value=72000000
RCC.HSE_VALUE=8000000
RCC.HSI_VALUE=8000000
RCC.LSE_VALUE=32768
RCC.PLLMUL=RCC_PLL_MUL9
RCC.PLLSourceVirtual=RCC_PLLSOURCE_HSE
RCC.SYSCLKFreq_VALUE=72000000
RCC.SYSCLKSourceVirtual=RCC_SYSCLKSOURCE_PLLCLK
RCC.USBFreq_Value=72000000
SH.COMP_DAC1_group.0=DAC_OUT1,DAC_OUT1
SH.S_TIM1_CH1.0=TIM1_CH1,PWM Generation1 CH1 CH1N
SH.S_TIM1_CH2.0=TIM1_CH2,PWM Generation2 CH2 CH2N
SH.S_TIM1_CH3.0=TIM1_CH3,PWM Generation3 CH3 CH3N
SH.S_TIM2_CH1_ETR.0=TIM2_CH1,Input_Capture2_from_TI1
SH.S_TIM2_CH1_ETR.1=TIM2_CH1,TriggerSource_TI1FP1
SH.S_TIM2_CH1_ETR.2=TIM2_CH1,Input_Capture1_from_TI1
SPI1.BaudRatePrescaler=SPI_BAUDRATEPRESCALER_64
SPI1.CLKPhase=SPI_PHASE_2EDGE
SPI1.CLKPolarity=SPI_POLARITY_HIGH
SPI1.CalculateBaudRate=1.125 MBits/s
SPI1.DataSize=SPI_DATASIZE_8BIT
SPI1.Direction=SPI_DIRECTION_2LINES
SPI1.Mode=SPI_MODE_MASTER
SPI1.VirtualType=VM_MASTER
TIM1.AutoReloadPreload=TIM_AUTORELOAD_PRELOAD_DISABLE
TIM1.AutomaticOutput=TIM_AUTOMATICOUTPUT_DISABLE
TIM1.Break2Filter=3
TIM1.Break2Polarity=TIM_BREAK2POLARITY_HIGH
TIM1.Break2State=TIM_BREAK2_ENABLE
TIM1.BreakFilter=0
TIM1.BreakPolarity=TIM_BREAKPOLARITY_HIGH
TIM1.BreakState=TIM_BREAK_DISABLE
TIM1.Channel-PWM\ Generation1\ CH1\ CH1N=TIM_CHANNEL_1
TIM1.Channel-PWM\ Generation2\ CH2\ CH2N=TIM_CHANNEL_2
TIM1.Channel-PWM\ Generation3\ CH3\ CH3N=TIM_CHANNEL_3
TIM1.Channel-PWM\ Generation4\ No\ Output=TIM_CHANNEL_4
TIM1.ClearInputSource=TIM_CLEARINPUTSOURCE_NONE
TIM1.ClockDivision=TIM_CLOCKDIVISION_DIV2
TIM1.CounterMode=TIM_COUNTERMODE_CENTERALIGNED1
TIM1.DeadTime=((DEAD_TIME_COUNTS) / 2)
TIM1.LockLevel=TIM_LOCKLEVEL_1
TIM1.OCIdleState_1=TIM_OCIDLESTATE_RESET
TIM1.OCIdleState_2=TIM_OCIDLESTATE_RESET
TIM1.OCIdleState_3=TIM_OCIDLESTATE_RESET
TIM1.OCIdleState_4=TIM_OCIDLESTATE_RESET
TIM1.OCMode_PWM-PWM\ Generation1\ CH1\ CH1N=TIM_OCMODE_PWM1
TIM1.OCMode_PWM-PWM\ Generation2\ CH2\ CH2N=TIM_OCMODE_PWM1
TIM1.OCMode_PWM-PWM\ Generation3\ CH3\ CH3N=TIM_OCMODE_PWM1
TIM1.OCMode_PWM-PWM\ Generation4\ No\ Output=TIM_OCMODE_PWM2
TIM1.OCNIdleState_1=TIM_OCNIDLESTATE_SET
TIM1.OCNIdleState_2=TIM_OCNIDLESTATE_SET
TIM1.OCNIdleState_3=TIM_OCNIDLESTATE_SET
TIM1.OCNPolarity_1=TIM_OCNPOLARITY_LOW
TIM1.OCNPolarity_2=TIM_OCNPOLARITY_LOW
TIM1.OCNPolarity_3=TIM_OCNPOLARITY_LOW
TIM1.OCPolarity_1=TIM_OCPOLARITY_HIGH
TIM1.OCPolarity_2=TIM_OCPOLARITY_HIGH
TIM1.OCPolarity_3=TIM_OCPOLARITY_HIGH
TIM1.OCPolarity_4=TIM_OCPOLARITY_HIGH
TIM1.OffStateIDLEMode=TIM_OSSI_ENABLE
TIM1.OffStateRunMode=TIM_OSSR_ENABLE
TIM1.Period=((PWM_PERIOD_CYCLES) / 2)
TIM1.Prescaler=((TIM_CLOCK_DIVIDER) - 1)
TIM1.Pulse-PWM\ Generation4\ No\ Output=(((PWM_PERIOD_CYCLES) / 2) - (HTMIN))
TIM1.RepetitionCounter=(REP_COUNTER)
TIM1.TIM_MasterOutputTrigger=TIM_TRGO_OC4REF
TIM1.TIM_MasterOutputTrigger2=TIM_TRGO2_RESET
TIM1.TIM_MasterSlaveMode=TIM_MASTERSLAVEMODE_DISABLE
TIM1.TIM_SlaveMode=TIM_SLAVEMODE_TRIGGER
TIM2.Channel-Input_Capture1_from_TI1=TIM_CHANNEL_1
TIM2.Channel-Input_Capture2_from_TI1=TIM_CHANNEL_2
TIM2.ICPolarity_CH2=TIM_INPUTCHANNELPOLARITY_FALLING
TIM2.Period=0xFFFFFFFF
USART1.BaudRate=115200
USART1.VirtualMode-Asynchronous=VM_ASYNC
USART1.WordLength=WORDLENGTH_8B
VP_COMP2_VS_VREFINT12.Mode=VREFINT_12
VP_COMP4_VS_VREFINT12.Mode=VREFINT_12
VP_COMP6_VS_VREFINT12.Mode=VREFINT_12
VP_MotorControl_MC_ENABLED.Mode=Enabled
VP_TIM1_VS_ClockSourceITR.Mode=TriggerSource_ITR1
VP_TIM1_VS_ControllerModeTrigger.Mode=Trigger Mode
VP_TIM1_VS_no_output4.Mode=PWM Generation4 No Output
VP_TIM2_VS_ControllerModeReset.Mode=Reset Mode
board=custom

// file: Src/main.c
/* USER CODE BEGIN Header */
/**
  ******************************************************************************
  * @file           : main.c
  * @brief          : Main program body
  ******************************************************************************
  * @attention
  *
  * <h2><center>&copy; Copyright (c) 2020 STMicroelectronics.
  * All rights reserved.</center></h2>
  *
  * This software component is licensed by ST under Ultimate Liberty license
  * SLA0044, the "License"; You may not use this file except in compliance with
  * the License. You may obtain a copy of the License at:
  *                             www.st.com/SLA0044
  *
  ******************************************************************************
  */
/* USER CODE END Header */
#include "main.h"
#include "motorcontrol.h"

/* USER CODE BEGIN Includes */
#include "stm32f3xx_hal.h"
/* USER CODE END Includes */

/* USER CODE BEGIN PD */

/* TMC6100 REGISTER LIST */
#define TMC6100_GCONF          	0x00
#define TMC6100_GSTAT          	0x01
#define TMC6100_IOIN		   	0x04
#define TMC6100_OTP_PROG       	0x06
#define TMC6100_OTP_READ       	0x07
#define TMC6100_FACTORY_CONF   	0x08
#define TMC6100_SHORT_CONF     	0x09
#define TMC6100_DRV_CONF       	0x0A

/* TMC6100 WRITE BYTE */
#define TMC6100_WRITE_BYTE		0x80

/* USER CODE END PD */

ADC_HandleTypeDef hadc1;
ADC_HandleTypeDef hadc3;

CAN_HandleTypeDef hcan;

COMP_HandleTypeDef hcomp2;
COMP_HandleTypeDef hcomp4;
COMP_HandleTypeDef hcomp6;

DAC_HandleTypeDef hdac;

SPI_HandleTypeDef hspi1;

TIM_HandleTypeDef htim1;
TIM_HandleTypeDef htim2;

UART_HandleTypeDef huart1;

/* USER CODE BEGIN PV */

/* Any data read from the TMC6100 driver chip will fill up the array.
 * While debugging, set breakpoints AFTER reading from a relevant register to view the data in this buffer.
 */
uint8_t SPIRxBuf [5];

/* Driver configuration */
uint8_t GCONF_Write [4] = {0x00, 0x00, 0x00, 0x40}; // {0x00, 0x00, 0x00, 0x40};
uint8_t SHORT_CONF_Write [4] = {0x60, 0x01, 0x05, 0x0A}; // {0x12, 0x01, 0x05, 0x0A}
uint8_t DRV_CONF_Write [4] = {0x00, 0x0E, 0x00, 0x00}; // {0x00, 0x0E, 0x00, 0x00}
uint8_t GSTAT_Write [4] = {0xFF, 0xFF, 0xFF, 0xFF};

/* USER CODE END PV */

void SystemClock_Config(void);
static void MX_GPIO_Init(void);
static void MX_ADC1_Init(void);
static void MX_ADC3_Init(void);
static void MX_COMP2_Init(void);
static void MX_COMP4_Init(void);
static void MX_COMP6_Init(void);
static void MX_TIM1_Init(void);
static void MX_TIM2_Init(void);
static void MX_USART1_UART_Init(void);
static void MX_CAN_Init(void);
static void MX_DAC_Init(void);
static void MX_SPI1_Init(void);
static void MX_NVIC_Init(void);
/* USER CODE BEGIN PFP */

void SPIread (uint8_t address, uint8_t *rxBuf);
void SPIwrite (uint8_t address, uint8_t *data);
void configureDriver (void);
void resetDriver (void);

/* USER CODE END PFP */

int main(void)
{

  /* MCU Configuration--------------------------------------------------------*/

  /* Reset of all peripherals, Initializes the Flash interface and the Systick. */
  HAL_Init();

  /* Configure the system clock */
  SystemClock_Config();

  /* Initialize all configured peripherals */
  MX_GPIO_Init();
  MX_ADC1_Init();
  MX_ADC3_Init();
  MX_COMP2_Init();
  MX_COMP4_Init();
  MX_COMP6_Init();
  MX_TIM1_Init();
  MX_TIM2_Init();
  MX_USART1_UART_Init();
  MX_MotorControl_Init();
  MX_CAN_Init();
  MX_DAC_Init();
  MX_SPI1_Init();

  /* Initialize interrupts */
  MX_NVIC_Init();
  /* USER CODE BEGIN 2 */

  /*Initialization of Electronic Speed Controller (STEVAL-ESC001V1)*/
  esc_boot(&ESC_M1);

  /* Reset the driver */
  resetDriver ();
  /* Write driver configuration to its registers through SPI */
  configureDriver ();

  /* DEBUG: read the registers after writing */
  SPIread (TMC6100_GCONF, SPIRxBuf);
  SPIread (TMC6100_SHORT_CONF, SPIRxBuf);
  SPIread (TMC6100_DRV_CONF, SPIRxBuf);

  /* USER CODE END 2 */

  /* Infinite loop */
  while (1)
  {

    /* USER CODE BEGIN 3 */

    /* Main routine for Electronic Speed Controller (STEVAL-ESC001V1) */
    esc_pwm_control(&ESC_M1);

    /* Driver fault handling */
    if (HAL_GPIO_ReadPin(GPIOB, GPIO_PIN_12)) {
    	/* Turn on fault LED */
    	HAL_GPIO_WritePin(GPIOB, GPIO_PIN_2, GPIO_PIN_SET);
    	/* DEBUG: read all input pins */
        SPIread (TMC6100_IOIN, SPIRxBuf);
        /* DEBUG: read fault register */
        SPIread (TMC6100_GSTAT, SPIRxBuf);
        /* Reset the driver */
        resetDriver ();
        /* DEBUG: read fault register */
        SPIread (TMC6100_GSTAT, SPIRxBuf);
        /* Write driver configuration to its registers through SPI */
        //configureDriver ();
    }
    else {
    	/* Turn off fault LED */
    	HAL_GPIO_WritePin(GPIOB, GPIO_PIN_2, GPIO_PIN_RESET);
    }

   }
  /* USER CODE END 3 */
}

void SystemClock_Config(void)
{
  RCC_OscInitTypeDef RCC_OscInitStruct = {0};
  RCC_ClkInitTypeDef RCC_ClkInitStruct = {0};
  RCC_PeriphCLKInitTypeDef PeriphClkInit = {0};

  /** Initializes the RCC Oscillators according to the specified parameters
  * in the RCC_OscInitTypeDef structure.
  */
  RCC_OscInitStruct.OscillatorType = RCC_OSCILLATORTYPE_HSE;
  RCC_OscInitStruct.HSEState = RCC_HSE_ON;
  RCC_OscInitStruct.HSEPredivValue = RCC_HSE_PREDIV_DIV1;
  RCC_OscInitStruct.HSIState = RCC_HSI_ON;
  RCC_OscInitStruct.PLL.PLLState = RCC_PLL_ON;
  RCC_OscInitStruct.PLL.PLLSource = RCC_PLLSOURCE_HSE;
  RCC_OscInitStruct.PLL.PLLMUL = RCC_PLL_MUL9;
  if (HAL_RCC_OscConfig(&RCC_OscInitStruct) != HAL_OK)
  {
    Error_Handler();
  }
  /** Initializes the CPU, AHB and APB buses clocks
  */
  RCC_ClkInitStruct.ClockType = RCC_CLOCKTYPE_HCLK|RCC_CLOCKTYPE_SYSCLK
                              |RCC_CLOCKTYPE_PCLK1|RCC_CLOCKTYPE_PCLK2;
  RCC_ClkInitStruct.SYSCLKSource = RCC_SYSCLKSOURCE_PLLCLK;
  RCC_ClkInitStruct.AHBCLKDivider = RCC_SYSCLK_DIV1;
  RCC_ClkInitStruct.APB1CLKDivider = RCC_HCLK_DIV2;
  RCC_ClkInitStruct.APB2CLKDivider = RCC_HCLK_DIV1;

  if (HAL_RCC_ClockConfig(&RCC_ClkInitStruct, FLASH_LATENCY_2) != HAL_OK)
  {
    Error_Handler();
  }
  PeriphClkInit.PeriphClockSelection = RCC_PERIPHCLK_USART1|RCC_PERIPHCLK_TIM1;
  PeriphClkInit.Usart1ClockSelection = RCC_USART1CLKSOURCE_PCLK2;
  PeriphClkInit.Tim1ClockSelection = RCC_TIM1CLK_HCLK;
  if (HAL_RCCEx_PeriphCLKConfig(&PeriphClkInit) != HAL_OK)
  {
    Error_Handler();
  }
}

/**
  * @brief NVIC Configuration.
  * @retval None
  */
static void MX_NVIC_Init(void)
{
  /* TIM1_BRK_TIM15_IRQn interrupt configuration */
  HAL_NVIC_SetPriority(TIM1_BRK_TIM15_IRQn, 4, 1);
  HAL_NVIC_EnableIRQ(TIM1_BRK_TIM15_IRQn);
  /* TIM1_UP_TIM16_IRQn interrupt configuration */
  HAL_NVIC_SetPriority(TIM1_UP_TIM16_IRQn, 0, 0);
  HAL_NVIC_EnableIRQ(TIM1_UP_TIM16_IRQn);
  /* ADC1_2_IRQn interrupt configuration */
  HAL_NVIC_SetPriority(ADC1_2_IRQn, 2, 0);
  HAL_NVIC_EnableIRQ(ADC1_2_IRQn);
  /* USART1_IRQn interrupt configuration */
  HAL_NVIC_SetPriority(USART1_IRQn, 3, 1);
  HAL_NVIC_EnableIRQ(USART1_IRQn);
  /* TIM2_IRQn interrupt configuration */
  HAL_NVIC_SetPriority(TIM2_IRQn, 3, 0);
  HAL_NVIC_EnableIRQ(TIM2_IRQn);
}

static void MX_ADC1_Init(void)
{

  ADC_MultiModeTypeDef multimode = {0};
  ADC_InjectionConfTypeDef sConfigInjected = {0};
  ADC_ChannelConfTypeDef sConfig = {0};

  /** Common config
  */
  hadc1.Instance = ADC1;
  hadc1.Init.ClockPrescaler = ADC_CLOCK_SYNC_PCLK_DIV1;
  hadc1.Init.Resolution = ADC_RESOLUTION_12B;
  hadc1.Init.ScanConvMode = ADC_SCAN_ENABLE;
  hadc1.Init.ContinuousConvMode = DISABLE;
  hadc1.Init.DiscontinuousConvMode = DISABLE;
  hadc1.Init.ExternalTrigConvEdge = ADC_EXTERNALTRIGCONVEDGE_NONE;
  hadc1.Init.ExternalTrigConv = ADC_SOFTWARE_START;
  hadc1.Init.DataAlign = ADC_DATAALIGN_LEFT;
  hadc1.Init.NbrOfConversion = 1;
  hadc1.Init.DMAContinuousRequests = DISABLE;
  hadc1.Init.EOCSelection = ADC_EOC_SINGLE_CONV;
  hadc1.Init.LowPowerAutoWait = DISABLE;
  hadc1.Init.Overrun = ADC_OVR_DATA_PRESERVED;
  if (HAL_ADC_Init(&hadc1) != HAL_OK)
  {
    Error_Handler();
  }
  /** Configure the ADC multi-mode
  */
  multimode.Mode = ADC_MODE_INDEPENDENT;
  if (HAL_ADCEx_MultiModeConfigChannel(&hadc1, &multimode) != HAL_OK)
  {
    Error_Handler();
  }
  /** Configure Injected Channel
  */
  sConfigInjected.InjectedChannel = ADC_CHANNEL_1;
  sConfigInjected.InjectedRank = ADC_INJECTED_RANK_1;
  sConfigInjected.InjectedSingleDiff = ADC_SINGLE_ENDED;
  sConfigInjected.InjectedNbrOfConversion = 3;
  sConfigInjected.InjectedSamplingTime = ADC_SAMPLETIME_7CYCLES_5;
  sConfigInjected.ExternalTrigInjecConvEdge = ADC_EXTERNALTRIGINJECCONV_EDGE_RISING;
  sConfigInjected.ExternalTrigInjecConv = ADC_EXTERNALTRIGINJECCONV_T1_TRGO;
  sConfigInjected.AutoInjectedConv = DISABLE;
  sConfigInjected.InjectedDiscontinuousConvMode = DISABLE;
  sConfigInjected.QueueInjectedContext = ENABLE;
  sConfigInjected.InjectedOffset = 0;
  sConfigInjected.InjectedOffsetNumber = ADC_OFFSET_NONE;
  if (HAL_ADCEx_InjectedConfigChannel(&hadc1, &sConfigInjected) != HAL_OK)
  {
    Error_Handler();
  }
  /** Configure Injected Channel
  */
  sConfigInjected.InjectedChannel = ADC_CHANNEL_2;
  sConfigInjected.InjectedRank = ADC_INJECTED_RANK_2;
  if (HAL_ADCEx_InjectedConfigChannel(&hadc1, &sConfigInjected) != HAL_OK)
  {
    Error_Handler();
  }
  /** Configure Injected Channel
  */
  sConfigInjected.InjectedChannel = ADC_CHANNEL_3;
  sConfigInjected.InjectedRank = ADC_INJECTED_RANK_3;
  if (HAL_ADCEx_InjectedConfigChannel(&hadc1, &sConfigInjected) != HAL_OK)
  {
    Error_Handler();
  }
  /** Configure Regular Channel
  */
  sConfig.Channel = ADC_CHANNEL_1;
  sConfig.Rank = ADC_REGULAR_RANK_1;
  sConfig.SingleDiff = ADC_SINGLE_ENDED;
  sConfig.SamplingTime = ADC_SAMPLETIME_19CYCLES_5;
  sConfig.OffsetNumber = ADC_OFFSET_NONE;
  sConfig.Offset = 0;
  if (HAL_ADC_ConfigChannel(&hadc1, &sConfig) != HAL_OK)
  {
    Error_Handler();
  }

}

static void MX_ADC3_Init(void)
{

  ADC_MultiModeTypeDef multimode = {0};
  ADC_ChannelConfTypeDef sConfig = {0};

  /** Common config
  */
  hadc3.Instance = ADC3;
  hadc3.Init.ClockPrescaler = ADC_CLOCK_SYNC_PCLK_DIV1;
  hadc3.Init.Resolution = ADC_RESOLUTION_12B;
  hadc3.Init.ScanConvMode = ADC_SCAN_DISABLE;
  hadc3.Init.ContinuousConvMode = DISABLE;
  hadc3.Init.DiscontinuousConvMode = DISABLE;
  hadc3.Init.ExternalTrigConvEdge = ADC_EXTERNALTRIGCONVEDGE_NONE;
  hadc3.Init.ExternalTrigConv = ADC_SOFTWARE_START;
  hadc3.Init.DataAlign = ADC_DATAALIGN_LEFT;
  hadc3.Init.NbrOfConversion = 1;
  hadc3.Init.DMAContinuousRequests = DISABLE;
  hadc3.Init.EOCSelection = ADC_EOC_SINGLE_CONV;
  hadc3.Init.LowPowerAutoWait = DISABLE;
  hadc3.Init.Overrun = ADC_OVR_DATA_PRESERVED;
  if (HAL_ADC_Init(&hadc3) != HAL_OK)
  {
    Error_Handler();
  }
  /** Configure the ADC multi-mode
  */
  multimode.Mode = ADC_MODE_INDEPENDENT;
  if (HAL_ADCEx_MultiModeConfigChannel(&hadc3, &multimode) != HAL_OK)
  {
    Error_Handler();
  }
  /** Configure Regular Channel
  */
  sConfig.Channel = ADC_CHANNEL_5;
  sConfig.Rank = ADC_REGULAR_RANK_1;
  sConfig.SingleDiff = ADC_SINGLE_ENDED;
  sConfig.SamplingTime = ADC_SAMPLETIME_19CYCLES_5;
  sConfig.OffsetNumber = ADC_OFFSET_NONE;
  sConfig.Offset = 0;
  if (HAL_ADC_ConfigChannel(&hadc3, &sConfig) != HAL_OK)
  {
    Error_Handler();
  }

}

static void MX_CAN_Init(void)
{

  hcan.Instance = CAN;
  hcan.Init.Prescaler = 16;
  hcan.Init.Mode = CAN_MODE_NORMAL;
  hcan.Init.SyncJumpWidth = CAN_SJW_1TQ;
  hcan.Init.TimeSeg1 = CAN_BS1_1TQ;
  hcan.Init.TimeSeg2 = CAN_BS2_1TQ;
  hcan.Init.TimeTriggeredMode = DISABLE;
  hcan.Init.AutoBusOff = DISABLE;
  hcan.Init.AutoWakeUp = DISABLE;
  hcan.Init.AutoRetransmission = DISABLE;
  hcan.Init.ReceiveFifoLocked = DISABLE;
  hcan.Init.TransmitFifoPriority = DISABLE;
  if (HAL_CAN_Init(&hcan) != HAL_OK)
  {
    Error_Handler();
  }

}

static void MX_COMP2_Init(void)
{

  hcomp2.Instance = COMP2;
  hcomp2.Init.InvertingInput = COMP_INVERTINGINPUT_1_2VREFINT;
  hcomp2.Init.NonInvertingInput = COMP_NONINVERTINGINPUT_IO1;
  hcomp2.Init.Output = COMP_OUTPUT_TIM1BKIN2;
  hcomp2.Init.OutputPol = COMP_OUTPUTPOL_NONINVERTED;
  hcomp2.Init.Hysteresis = COMP_HYSTERESIS_NONE;
  hcomp2.Init.BlankingSrce = COMP_BLANKINGSRCE_NONE;
  hcomp2.Init.Mode = COMP_MODE_HIGHSPEED;
  hcomp2.Init.WindowMode = COMP_WINDOWMODE_DISABLE;
  hcomp2.Init.TriggerMode = COMP_TRIGGERMODE_NONE;
  if (HAL_COMP_Init(&hcomp2) != HAL_OK)
  {
    Error_Handler();
  }

}

static void MX_COMP4_Init(void)
{

  hcomp4.Instance = COMP4;
  hcomp4.Init.InvertingInput = COMP_INVERTINGINPUT_1_2VREFINT;
  hcomp4.Init.NonInvertingInput = COMP_NONINVERTINGINPUT_IO1;
  hcomp4.Init.Output = COMP_OUTPUT_TIM1BKIN2;
  hcomp4.Init.OutputPol = COMP_OUTPUTPOL_NONINVERTED;
  hcomp4.Init.Hysteresis = COMP_HYSTERESIS_NONE;
  hcomp4.Init.BlankingSrce = COMP_BLANKINGSRCE_NONE;
  hcomp4.Init.Mode = COMP_MODE_HIGHSPEED;
  hcomp4.Init.WindowMode = COMP_WINDOWMODE_DISABLE;
  hcomp4.Init.TriggerMode = COMP_TRIGGERMODE_NONE;
  if (HAL_COMP_Init(&hcomp4) != HAL_OK)
  {
    Error_Handler();
  }

}

static void MX_COMP6_Init(void)
{

  hcomp6.Instance = COMP6;
  hcomp6.Init.InvertingInput = COMP_INVERTINGINPUT_1_2VREFINT;
  hcomp6.Init.NonInvertingInput = COMP_NONINVERTINGINPUT_IO2;
  hcomp6.Init.Output = COMP_OUTPUT_TIM1BKIN2;
  hcomp6.Init.OutputPol = COMP_OUTPUTPOL_NONINVERTED;
  hcomp6.Init.Hysteresis = COMP_HYSTERESIS_NONE;
  hcomp6.Init.BlankingSrce = COMP_BLANKINGSRCE_NONE;
  hcomp6.Init.Mode = COMP_MODE_HIGHSPEED;
  hcomp6.Init.WindowMode = COMP_WINDOWMODE_DISABLE;
  hcomp6.Init.TriggerMode = COMP_TRIGGERMODE_NONE;
  if (HAL_COMP_Init(&hcomp6) != HAL_OK)
  {
    Error_Handler();
  }

}

static void MX_DAC_Init(void)
{

  DAC_ChannelConfTypeDef sConfig = {0};

  /** DAC Initialization
  */
  hdac.Instance = DAC;
  if (HAL_DAC_Init(&hdac) != HAL_OK)
  {
    Error_Handler();
  }
  /** DAC channel OUT1 config
  */
  sConfig.DAC_Trigger = DAC_TRIGGER_NONE;
  sConfig.DAC_OutputBuffer = DAC_OUTPUTBUFFER_ENABLE;
  if (HAL_DAC_ConfigChannel(&hdac, &sConfig, DAC_CHANNEL_1) != HAL_OK)
  {
    Error_Handler();
  }

}

static void MX_SPI1_Init(void)
{

  /* SPI1 parameter configuration*/
  hspi1.Instance = SPI1;
  hspi1.Init.Mode = SPI_MODE_MASTER;
  hspi1.Init.Direction = SPI_DIRECTION_2LINES;
  hspi1.Init.DataSize = SPI_DATASIZE_8BIT;
  hspi1.Init.CLKPolarity = SPI_POLARITY_HIGH;
  hspi1.Init.CLKPhase = SPI_PHASE_2EDGE;
  hspi1.Init.NSS = SPI_NSS_SOFT;
  hspi1.Init.BaudRatePrescaler = SPI_BAUDRATEPRESCALER_64;
  hspi1.Init.FirstBit = SPI_FIRSTBIT_MSB;
  hspi1.Init.TIMode = SPI_TIMODE_DISABLE;
  hspi1.Init.CRCCalculation = SPI_CRCCALCULATION_DISABLE;
  hspi1.Init.CRCPolynomial = 7;
  hspi1.Init.CRCLength = SPI_CRC_LENGTH_DATASIZE;
  hspi1.Init.NSSPMode = SPI_NSS_PULSE_DISABLE;
  if (HAL_SPI_Init(&hspi1) != HAL_OK)
  {
    Error_Handler();
  }

}

static void MX_TIM1_Init(void)
{

  TIM_SlaveConfigTypeDef sSlaveConfig = {0};
  TIM_MasterConfigTypeDef sMasterConfig = {0};
  TIM_OC_InitTypeDef sConfigOC = {0};
  TIM_BreakDeadTimeConfigTypeDef sBreakDeadTimeConfig = {0};

  htim1.Instance = TIM1;
  htim1.Init.Prescaler = ((TIM_CLOCK_DIVIDER) - 1);
  htim1.Init.CounterMode = TIM_COUNTERMODE_CENTERALIGNED1;
  htim1.Init.Period = ((PWM_PERIOD_CYCLES) / 2);
  htim1.Init.ClockDivision = TIM_CLOCKDIVISION_DIV2;
  htim1.Init.RepetitionCounter = (REP_COUNTER);
  htim1.Init.AutoReloadPreload = TIM_AUTORELOAD_PRELOAD_DISABLE;
  if (HAL_TIM_Base_Init(&htim1) != HAL_OK)
  {
    Error_Handler();
  }
  if (HAL_TIM_PWM_Init(&htim1) != HAL_OK)
  {
    Error_Handler();
  }
  sSlaveConfig.SlaveMode = TIM_SLAVEMODE_TRIGGER;
  sSlaveConfig.InputTrigger = TIM_TS_ITR1;
  if (HAL_TIM_SlaveConfigSynchro(&htim1, &sSlaveConfig) != HAL_OK)
  {
    Error_Handler();
  }
  sMasterConfig.MasterOutputTrigger = TIM_TRGO_OC4REF;
  sMasterConfig.MasterOutputTrigger2 = TIM_TRGO2_RESET;
  sMasterConfig.MasterSlaveMode = TIM_MASTERSLAVEMODE_DISABLE;
  if (HAL_TIMEx_MasterConfigSynchronization(&htim1, &sMasterConfig) != HAL_OK)
  {
    Error_Handler();
  }
  sConfigOC.OCMode = TIM_OCMODE_PWM1;
  sConfigOC.Pulse = 0;
  sConfigOC.OCPolarity = TIM_OCPOLARITY_HIGH;
  sConfigOC.OCNPolarity = TIM_OCNPOLARITY_LOW;
  sConfigOC.OCFastMode = TIM_OCFAST_DISABLE;
  sConfigOC.OCIdleState = TIM_OCIDLESTATE_RESET;
  sConfigOC.OCNIdleState = TIM_OCNIDLESTATE_SET;
  if (HAL_TIM_PWM_ConfigChannel(&htim1, &sConfigOC, TIM_CHANNEL_1) != HAL_OK)
  {
    Error_Handler();
  }
  if (HAL_TIM_PWM_ConfigChannel(&htim1, &sConfigOC, TIM_CHANNEL_2) != HAL_OK)
  {
    Error_Handler();
  }
  if (HAL_TIM_PWM_ConfigChannel(&htim1, &sConfigOC, TIM_CHANNEL_3) != HAL_OK)
  {
    Error_Handler();
  }
  sConfigOC.OCMode = TIM_OCMODE_PWM2;
  sConfigOC.Pulse = (((PWM_PERIOD_CYCLES) / 2) - (HTMIN));
  sConfigOC.OCNIdleState = TIM_OCNIDLESTATE_RESET;
  if (HAL_TIM_PWM_ConfigChannel(&htim1, &sConfigOC, TIM_CHANNEL_4) != HAL_OK)
  {
    Error_Handler();
  }
  sBreakDeadTimeConfig.OffStateRunMode = TIM_OSSR_ENABLE;
  sBreakDeadTimeConfig.OffStateIDLEMode = TIM_OSSI_ENABLE;
  sBreakDeadTimeConfig.LockLevel = TIM_LOCKLEVEL_1;
  sBreakDeadTimeConfig.DeadTime = ((DEAD_TIME_COUNTS) / 2);
  sBreakDeadTimeConfig.BreakState = TIM_BREAK_DISABLE;
  sBreakDeadTimeConfig.BreakPolarity = TIM_BREAKPOLARITY_HIGH;
  sBreakDeadTimeConfig.BreakFilter = 0;
  sBreakDeadTimeConfig.Break2State = TIM_BREAK2_ENABLE;
  sBreakDeadTimeConfig.Break2Polarity = TIM_BREAK2POLARITY_HIGH;
  sBreakDeadTimeConfig.Break2Filter = 3;
  sBreakDeadTimeConfig.AutomaticOutput = TIM_AUTOMATICOUTPUT_DISABLE;
  if (HAL_TIMEx_ConfigBreakDeadTime(&htim1, &sBreakDeadTimeConfig) != HAL_OK)
  {
    Error_Handler();
  }
  HAL_TIM_MspPostInit(&htim1);

}

static void MX_TIM2_Init(void)
{

  TIM_SlaveConfigTypeDef sSlaveConfig = {0};
  TIM_MasterConfigTypeDef sMasterConfig = {0};
  TIM_IC_InitTypeDef sConfigIC = {0};

  htim2.Instance = TIM2;
  htim2.Init.Prescaler = 0;
  htim2.Init.CounterMode = TIM_COUNTERMODE_UP;
  htim2.Init.Period = 0xFFFFFFFF;
  htim2.Init.ClockDivision = TIM_CLOCKDIVISION_DIV1;
  htim2.Init.AutoReloadPreload = TIM_AUTORELOAD_PRELOAD_DISABLE;
  if (HAL_TIM_Base_Init(&htim2) != HAL_OK)
  {
    Error_Handler();
  }
  if (HAL_TIM_IC_Init(&htim2) != HAL_OK)
  {
    Error_Handler();
  }
  sSlaveConfig.SlaveMode = TIM_SLAVEMODE_RESET;
  sSlaveConfig.InputTrigger = TIM_TS_TI1FP1;
  sSlaveConfig.TriggerPolarity = TIM_INPUTCHANNELPOLARITY_RISING;
  sSlaveConfig.TriggerFilter = 0;
  if (HAL_TIM_SlaveConfigSynchro(&htim2, &sSlaveConfig) != HAL_OK)
  {
    Error_Handler();
  }
  sMasterConfig.MasterOutputTrigger = TIM_TRGO_RESET;
  sMasterConfig.MasterSlaveMode = TIM_MASTERSLAVEMODE_DISABLE;
  if (HAL_TIMEx_MasterConfigSynchronization(&htim2, &sMasterConfig) != HAL_OK)
  {
    Error_Handler();
  }
  sConfigIC.ICPolarity = TIM_INPUTCHANNELPOLARITY_RISING;
  sConfigIC.ICSelection = TIM_ICSELECTION_DIRECTTI;
  sConfigIC.ICPrescaler = TIM_ICPSC_DIV1;
  sConfigIC.ICFilter = 0;
  if (HAL_TIM_IC_ConfigChannel(&htim2, &sConfigIC, TIM_CHANNEL_1) != HAL_OK)
  {
    Error_Handler();
  }
  sConfigIC.ICPolarity = TIM_INPUTCHANNELPOLARITY_FALLING;
  sConfigIC.ICSelection = TIM_ICSELECTION_INDIRECTTI;
  if (HAL_TIM_IC_ConfigChannel(&htim2, &sConfigIC, TIM_CHANNEL_2) != HAL_OK)
  {
    Error_Handler();
  }

}

static void MX_USART1_UART_Init(void)
{

  huart1.Instance = USART1;
  huart1.Init.BaudRate = 115200;
  huart1.Init.WordLength = UART_WORDLENGTH_8B;
  huart1.Init.StopBits = UART_STOPBITS_1;
  huart1.Init.Parity = UART_PARITY_NONE;
  huart1.Init.Mode = UART_MODE_TX_RX;
  huart1.Init.HwFlowCtl = UART_HWCONTROL_NONE;
  huart1.Init.OverSampling = UART_OVERSAMPLING_16;
  huart1.Init.OneBitSampling = UART_ONE_BIT_SAMPLE_DISABLE;
  huart1.AdvancedInit.AdvFeatureInit = UART_ADVFEATURE_NO_INIT;
  if (HAL_UART_Init(&huart1) != HAL_OK)
  {
    Error_Handler();
  }

}

static void MX_GPIO_Init(void)
{
  GPIO_InitTypeDef GPIO_InitStruct = {0};

  /* GPIO Ports Clock Enable */
  __HAL_RCC_GPIOF_CLK_ENABLE();
  __HAL_RCC_GPIOA_CLK_ENABLE();
  __HAL_RCC_GPIOB_CLK_ENABLE();

  /*Configure GPIO pin Output Level */
  HAL_GPIO_WritePin(GPIOB, STAT_LED_Pin|DRV_EN_Pin, GPIO_PIN_RESET);

  /*Configure GPIO pin Output Level */
  HAL_GPIO_WritePin(SPI1_NSS_SOFT_GPIO_Port, SPI1_NSS_SOFT_Pin, GPIO_PIN_RESET);

  /*Configure GPIO pin : STAT_LED_Pin */
  GPIO_InitStruct.Pin = STAT_LED_Pin;
  GPIO_InitStruct.Mode = GPIO_MODE_OUTPUT_PP;
  GPIO_InitStruct.Pull = GPIO_PULLDOWN;
  GPIO_InitStruct.Speed = GPIO_SPEED_FREQ_LOW;
  HAL_GPIO_Init(STAT_LED_GPIO_Port, &GPIO_InitStruct);

  /*Configure GPIO pin : DRV_EN_Pin */
  GPIO_InitStruct.Pin = DRV_EN_Pin;
  GPIO_InitStruct.Mode = GPIO_MODE_OUTPUT_PP;
  GPIO_InitStruct.Pull = GPIO_NOPULL;
  GPIO_InitStruct.Speed = GPIO_SPEED_FREQ_LOW;
  HAL_GPIO_Init(DRV_EN_GPIO_Port, &GPIO_InitStruct);

  /*Configure GPIO pin : DRV_FAULT_Pin */
  GPIO_InitStruct.Pin = DRV_FAULT_Pin;
  GPIO_InitStruct.Mode = GPIO_MODE_INPUT;
  GPIO_InitStruct.Pull = GPIO_NOPULL;
  HAL_GPIO_Init(DRV_FAULT_GPIO_Port, &GPIO_InitStruct);

  /*Configure GPIO pin : SPI1_NSS_SOFT_Pin */
  GPIO_InitStruct.Pin = SPI1_NSS_SOFT_Pin;
  GPIO_InitStruct.Mode = GPIO_MODE_OUTPUT_PP;
  GPIO_InitStruct.Pull = GPIO_PULLUP;
  GPIO_InitStruct.Speed = GPIO_SPEED_FREQ_HIGH;
  HAL_GPIO_Init(SPI1_NSS_SOFT_GPIO_Port, &GPIO_InitStruct);

}

/* USER CODE BEGIN 4 */

void SPIread (uint8_t address, uint8_t *inputBuffer) {
	uint8_t outputBuffer [5] = {address, 0x00, 0x00, 0x00, 0x00};
	/* READ */
	/* Pull NSS LOW before beginning the transaction*/
	HAL_GPIO_WritePin(GPIOA, GPIO_PIN_15, GPIO_PIN_RESET);
	/* Transaction */
	HAL_SPI_TransmitReceive(&hspi1, outputBuffer, inputBuffer, 5, 1);
	/* Transaction is over; pull NSS HIGH once again */
	HAL_GPIO_WritePin(GPIOA, GPIO_PIN_15, GPIO_PIN_SET);
}

void SPIwrite (uint8_t address, uint8_t *data) {
	uint8_t outputBuffer [5] = {address + TMC6100_WRITE_BYTE, data [0], data [1], data [2], data [3]};
	uint8_t inputBuffer [5];
	/* READ */
	/* Pull NSS LOW before beginning the transaction*/
	HAL_GPIO_WritePin(GPIOA, GPIO_PIN_15, GPIO_PIN_RESET);
	/* Transaction */
	HAL_SPI_TransmitReceive(&hspi1, outputBuffer, inputBuffer, 5, 1);
	/* Transaction is over; pull NSS HIGH once again */
	HAL_GPIO_WritePin(GPIOA, GPIO_PIN_15, GPIO_PIN_SET);
}

void configureDriver (void) {
	SPIwrite (TMC6100_GCONF, GCONF_Write);
	SPIwrite (TMC6100_SHORT_CONF, SHORT_CONF_Write);
	SPIwrite (TMC6100_DRV_CONF, DRV_CONF_Write);
}

void resetDriver (void) {
	HAL_GPIO_WritePin(GPIOB, GPIO_PIN_10, GPIO_PIN_RESET);
	HAL_Delay (50);
	HAL_GPIO_WritePin(GPIOB, GPIO_PIN_10, GPIO_PIN_SET);
}

/* USER CODE END 4 */

void Error_Handler(void)
{
}

/************************ (C) COPYRIGHT STMicroelectronics *****END OF FILE****/
